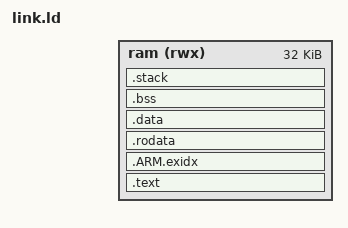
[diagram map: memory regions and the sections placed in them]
/**
 * Linker script for F1C100S internal SRAM
 * F1C100S has 32KB SRAM at 0x00000000
 *
 * SPDX-License-Identifier: Apache-2.0
 */

OUTPUT_FORMAT("elf32-littlearm", "elf32-littlearm", "elf32-littlearm")
OUTPUT_ARCH(arm)
SEARCH_DIR(.)

/* Memory Spaces Definitions */
MEMORY
{
  ram   (rwx) : ORIGIN = __RAM_BASE, LENGTH = 32K
}

/* The stack size used by the application */
STACK_SIZE = 0x800; /* 2KB */

ENTRY(reset)

/* Section Definitions */
SECTIONS
{
    .text :
    {
    . = ALIGN(4);
    PROVIDE(__spl_start = .);
    *(.text .text.*)
    . = ALIGN(4);
    } > ram

    . = ALIGN(4);

    .ARM.exidx : {
        __exidx_start = .;
        *(.ARM.exidx* .gnu.linkonce.armexidx.*)
        __exidx_end = .;
    } > ram

    .rodata :
    {
        . = ALIGN(4);
        *(.rodata .rodata.*)
        . = ALIGN(4);
    } > ram

    .data :
    {
        . = ALIGN(4);
        *(.data .data.*)
        . = ALIGN(4);
    } > ram

    PROVIDE(__spl_end = .);
    PROVIDE(__spl_size = __spl_end - __spl_start);

    /* .bss section which is used for uninitialized data */
    .bss (NOLOAD) :
    {
        . = ALIGN(4);
        _sbss = . ;
        *(.bss .bss.*)
        *(COMMON)
        . = ALIGN(4);
        _ebss = . ;
    } > ram

    .stack (NOLOAD):
    {
        . = ALIGN(8);
        __stack_srv_start = .;
        . += STACK_SIZE;
        __stack_srv_end = .;
    } > ram

    . = ALIGN(4);
    _end = . ;
}
